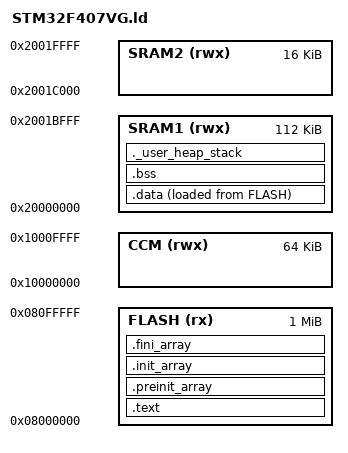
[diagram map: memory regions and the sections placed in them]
/* STM32F407VG Linker Script
 * Flash: 1MB  @ 0x08000000
 * SRAM1: 112KB @ 0x20000000
 * SRAM2: 16KB  @ 0x2001C000
 * CCM:   64KB  @ 0x10000000 (CPU only, no DMA)
 */

ENTRY(Reset_Handler)

MEMORY
{
    FLASH (rx)  : ORIGIN = 0x08000000, LENGTH = 1024K
    SRAM1 (rwx) : ORIGIN = 0x20000000, LENGTH = 112K
    SRAM2 (rwx) : ORIGIN = 0x2001C000, LENGTH = 16K
    CCM   (rwx) : ORIGIN = 0x10000000, LENGTH = 64K
}

_estack = ORIGIN(SRAM1) + LENGTH(SRAM1);

SECTIONS
{
    .text :
    {
        KEEP(*(.isr_vector))
        *(.text)
        *(.text*)
        *(.rodata)
        *(.rodata*)
        . = ALIGN(4);
        _etext = .;
    } > FLASH

    .preinit_array :
    {
        PROVIDE_HIDDEN(__preinit_array_start = .);
        KEEP(*(.preinit_array*))
        PROVIDE_HIDDEN(__preinit_array_end = .);
    } > FLASH

    .init_array :
    {
        PROVIDE_HIDDEN(__init_array_start = .);
        KEEP(*(SORT(.init_array.*)))
        KEEP(*(.init_array*))
        PROVIDE_HIDDEN(__init_array_end = .);
    } > FLASH

    .fini_array :
    {
        PROVIDE_HIDDEN(__fini_array_start = .);
        KEEP(*(SORT(.fini_array.*)))
        KEEP(*(.fini_array*))
        PROVIDE_HIDDEN(__fini_array_end = .);
    } > FLASH

    _sidata = LOADADDR(.data);

    .data :
    {
        . = ALIGN(4);
        _sdata = .;
        *(.data)
        *(.data*)
        . = ALIGN(4);
        _edata = .;
    } > SRAM1 AT > FLASH

    .bss :
    {
        . = ALIGN(4);
        _sbss = .;
        *(.bss)
        *(.bss*)
        *(COMMON)
        . = ALIGN(4);
        _ebss = .;
    } > SRAM1

    _Min_Heap_Size  = 0x400;
    _Min_Stack_Size = 0x400;

    ._user_heap_stack :
    {
        . = ALIGN(8);
        PROVIDE(end = .);
        . = . + _Min_Heap_Size;
        . = . + _Min_Stack_Size;
        . = ALIGN(8);
    } > SRAM1

    /DISCARD/ :
    {
        libc.a (*)
        libm.a (*)
        libgcc.a (*)
    }
}
